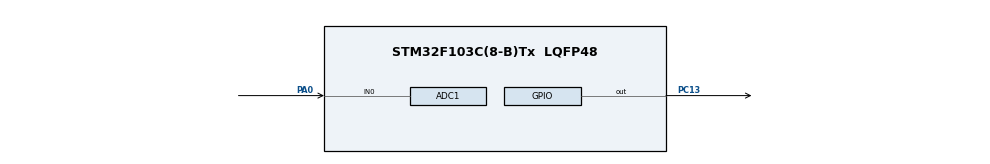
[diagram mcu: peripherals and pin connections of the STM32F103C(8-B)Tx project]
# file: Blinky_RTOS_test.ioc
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ADC1.Channel-0\#ChannelRegularConversion=ADC_CHANNEL_0
ADC1.ContinuousConvMode=ENABLE
ADC1.NbrOfConversion=1
ADC1.NbrOfConversionFlag=1
ADC1.Rank-0\#ChannelRegularConversion=1
ADC1.SamplingTime-0\#ChannelRegularConversion=ADC_SAMPLETIME_1CYCLE_5
ADC1.master=1
Mcu.Family=STM32F1
Mcu.Name=STM32F103C(8-B)Tx
Mcu.Package=LQFP48
NVIC.ADC1_2_IRQn=true\:6\:0\:true\:false\:true\:true\:true\:true
NVIC.PriorityGroup=NVIC_PRIORITYGROUP_4
NVIC.TIM1_UP_IRQn=true\:15\:0\:false\:false\:true\:false\:true\:true
NVIC.TimeBase=TIM1_UP_IRQn
NVIC.TimeBaseIP=TIM1
PA0-WKUP.Signal=ADCx_IN0
PC13-TAMPER-RTC.Signal=GPIO_Output
PD0-OSC_IN.Mode=HSE-External-Oscillator
PD0-OSC_IN.Signal=RCC_OSC_IN
PD1-OSC_OUT.Mode=HSE-External-Oscillator
PD1-OSC_OUT.Signal=RCC_OSC_OUT
ProjectManager.HeapSize=0x200
ProjectManager.StackSize=0x400
ProjectManager.TargetToolchain=STM32CubeIDE
RCC.APB1Freq_Value=8000000
RCC.APB2Freq_Value=8000000
SH.ADCx_IN0.0=ADC1_IN0,IN0
VP_SYS_VS_tim1.Mode=TIM1
board=custom

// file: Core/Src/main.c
/* USER CODE BEGIN Header */
/**
  ******************************************************************************
  * @file           : main.c
  * @brief          : Main program body
  ******************************************************************************
  * @attention
  *
  * Copyright (c) 2024 STMicroelectronics.
  * All rights reserved.
  *
  * This software is licensed under terms that can be found in the LICENSE file
  * in the root directory of this software component.
  * If no LICENSE file comes with this software, it is provided AS-IS.
  *
  ******************************************************************************
  */
/* USER CODE END Header */
#include "main.h"

/* USER CODE BEGIN Includes */
#include "FreeRTOS.h"
#include "task.h"
/* USER CODE END Includes */

/* USER CODE BEGIN PTD */

enum voltage{
	low_voltage = 0,
	mid_voltage,
	high_voltage
};

/* USER CODE END PTD */

ADC_HandleTypeDef hadc1;

/* USER CODE BEGIN PV */
TaskHandle_t LED_BLINK_hndl;
TaskHandle_t MEASURE_hndl;

uint8_t VOLTAGE_LEVEL = low_voltage;

/* USER CODE END PV */

void SystemClock_Config(void);
static void MX_GPIO_Init(void);
static void MX_ADC1_Init(void);
/* USER CODE BEGIN PFP */
void LED_BLINK_task(void* vParameters);
void MEASURE_task(void* vParameters);
/* USER CODE END PFP */

int main(void)
{
  /* USER CODE BEGIN 1 */
	BaseType_t Status;
  /* USER CODE END 1 */

  /* MCU Configuration--------------------------------------------------------*/

  /* Reset of all peripherals, Initializes the Flash interface and the Systick. */
  HAL_Init();

  /* Configure the system clock */
  SystemClock_Config();

  /* Initialize all configured peripherals */
  MX_GPIO_Init();
  MX_ADC1_Init();
  /* USER CODE BEGIN 2 */

  Status = xTaskCreate(LED_BLINK_task, "LED BLINK TASK", 100, 0, 1, &LED_BLINK_hndl);
  configASSERT(Status == pdPASS);

  Status = xTaskCreate(MEASURE_task, "MEASURE TASK", 100, 0, 1, &MEASURE_hndl);
  configASSERT(Status == pdPASS);

  vTaskStartScheduler();

  /* USER CODE END 2 */

  /* Infinite loop */
  while (1)
  {

  }
}

void SystemClock_Config(void)
{
  RCC_OscInitTypeDef RCC_OscInitStruct = {0};
  RCC_ClkInitTypeDef RCC_ClkInitStruct = {0};
  RCC_PeriphCLKInitTypeDef PeriphClkInit = {0};

  /** Initializes the RCC Oscillators according to the specified parameters
  * in the RCC_OscInitTypeDef structure.
  */
  RCC_OscInitStruct.OscillatorType = RCC_OSCILLATORTYPE_HSI;
  RCC_OscInitStruct.HSIState = RCC_HSI_ON;
  RCC_OscInitStruct.HSICalibrationValue = RCC_HSICALIBRATION_DEFAULT;
  RCC_OscInitStruct.PLL.PLLState = RCC_PLL_NONE;
  if (HAL_RCC_OscConfig(&RCC_OscInitStruct) != HAL_OK)
  {
    Error_Handler();
  }

  /** Initializes the CPU, AHB and APB buses clocks
  */
  RCC_ClkInitStruct.ClockType = RCC_CLOCKTYPE_HCLK|RCC_CLOCKTYPE_SYSCLK
                              |RCC_CLOCKTYPE_PCLK1|RCC_CLOCKTYPE_PCLK2;
  RCC_ClkInitStruct.SYSCLKSource = RCC_SYSCLKSOURCE_HSI;
  RCC_ClkInitStruct.AHBCLKDivider = RCC_SYSCLK_DIV1;
  RCC_ClkInitStruct.APB1CLKDivider = RCC_HCLK_DIV1;
  RCC_ClkInitStruct.APB2CLKDivider = RCC_HCLK_DIV1;

  if (HAL_RCC_ClockConfig(&RCC_ClkInitStruct, FLASH_LATENCY_0) != HAL_OK)
  {
    Error_Handler();
  }
  PeriphClkInit.PeriphClockSelection = RCC_PERIPHCLK_ADC;
  PeriphClkInit.AdcClockSelection = RCC_ADCPCLK2_DIV2;
  if (HAL_RCCEx_PeriphCLKConfig(&PeriphClkInit) != HAL_OK)
  {
    Error_Handler();
  }
}

static void MX_ADC1_Init(void)
{

  ADC_ChannelConfTypeDef sConfig = {0};

  /** Common config
  */
  hadc1.Instance = ADC1;
  hadc1.Init.ScanConvMode = ADC_SCAN_DISABLE;
  hadc1.Init.ContinuousConvMode = ENABLE;
  hadc1.Init.DiscontinuousConvMode = DISABLE;
  hadc1.Init.ExternalTrigConv = ADC_SOFTWARE_START;
  hadc1.Init.DataAlign = ADC_DATAALIGN_RIGHT;
  hadc1.Init.NbrOfConversion = 1;
  if (HAL_ADC_Init(&hadc1) != HAL_OK)
  {
    Error_Handler();
  }

  /** Configure Regular Channel
  */
  sConfig.Channel = ADC_CHANNEL_0;
  sConfig.Rank = ADC_REGULAR_RANK_1;
  sConfig.SamplingTime = ADC_SAMPLETIME_1CYCLE_5;
  if (HAL_ADC_ConfigChannel(&hadc1, &sConfig) != HAL_OK)
  {
    Error_Handler();
  }

}

static void MX_GPIO_Init(void)
{
  GPIO_InitTypeDef GPIO_InitStruct = {0};

  /* GPIO Ports Clock Enable */
  __HAL_RCC_GPIOC_CLK_ENABLE();
  __HAL_RCC_GPIOD_CLK_ENABLE();
  __HAL_RCC_GPIOA_CLK_ENABLE();

  /*Configure GPIO pin Output Level */
  HAL_GPIO_WritePin(GPIOC, GPIO_PIN_13, GPIO_PIN_RESET);

  /*Configure GPIO pin : PC13 */
  GPIO_InitStruct.Pin = GPIO_PIN_13;
  GPIO_InitStruct.Mode = GPIO_MODE_OUTPUT_PP;
  GPIO_InitStruct.Pull = GPIO_NOPULL;
  GPIO_InitStruct.Speed = GPIO_SPEED_FREQ_LOW;
  HAL_GPIO_Init(GPIOC, &GPIO_InitStruct);

}

/* USER CODE BEGIN 4 */
void LED_BLINK_task(void* vParameters)
{
	TickType_t last_time_woken = xTaskGetTickCount();
	while(1)
	{
		if(VOLTAGE_LEVEL == low_voltage)
		{
			vTaskDelayUntil(&last_time_woken, pdMS_TO_TICKS(1000));
		}
		else {
			vTaskDelayUntil(&last_time_woken, pdMS_TO_TICKS(200));
		}

		HAL_GPIO_TogglePin(GPIOC, GPIO_PIN_13);
	}
}

void MEASURE_task(void* vParameters)
{

	while(1)
	{
		vTaskDelay(pdMS_TO_TICKS(2000));
		HAL_ADC_Start_IT(&hadc1);
	}
}

void HAL_ADC_ConvCpltCallback(ADC_HandleTypeDef* hadc)
{
	uint32_t ADC_VALUE = 0;

	ADC_VALUE = HAL_ADC_GetValue(&hadc1);

	if(ADC_VALUE <= 2000)
	{
		VOLTAGE_LEVEL = low_voltage;
	}
	else if(ADC_VALUE > 2000 && ADC_VALUE <3500)
	{
		VOLTAGE_LEVEL = mid_voltage;
	}
	else
	{
		VOLTAGE_LEVEL = high_voltage;
	}

	HAL_ADC_Stop_IT(&hadc1);
}
/* USER CODE END 4 */

void HAL_TIM_PeriodElapsedCallback(TIM_HandleTypeDef *htim)
{
  if (htim->Instance == TIM1) {
    HAL_IncTick();
  }
}

void Error_Handler(void)
{
  __disable_irq();
  while (1)
  {
  }
}
